# regs-internal register map
Registers are 32-bit, access not given, no defined reset value unless marked. A register's access mark holds for its fields unless they carry their own. Addresses are absolute; registers are grouped by the start of their names; [hi:lo] are bit positions; {n}, {i} and the like mark numbered series; 'fields as' and 'values as' point back to an identical list.

## MEM
{0x40005000+4i} MEM_PROT_{i} (i=0..7)
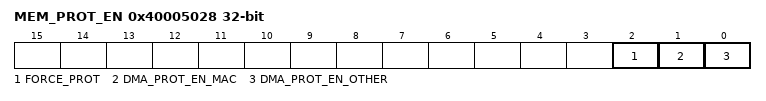
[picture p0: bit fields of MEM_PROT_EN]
0x40005028 MEM_PROT_EN
  [2] FORCE_PROT, [1] DMA_PROT_EN_MAC, [0] DMA_PROT_EN_OTHER

## WDOG
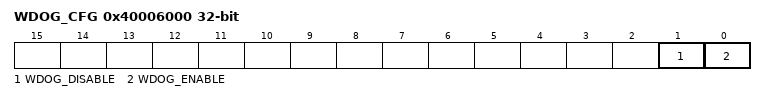
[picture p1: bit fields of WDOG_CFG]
0x40006000 WDOG_CFG
  [1] WDOG_DISABLE, [0] WDOG_ENABLE
0x40006004 WDOG_KEY
  [15:0] WDOG_KEY_FIELD
0x40006008 WDOG_RESET

## CAL
0x40007000 CAL_ADC_DATA
  [15:0] CAL_ADC_DATA
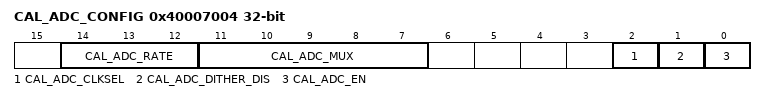
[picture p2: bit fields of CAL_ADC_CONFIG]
0x40007004 CAL_ADC_CONFIG
  [14:12] CAL_ADC_RATE, [11:7] CAL_ADC_MUX, [2] CAL_ADC_CLKSEL, [1] CAL_ADC_DITHER_DIS, [0] CAL_ADC_EN

## FLASH
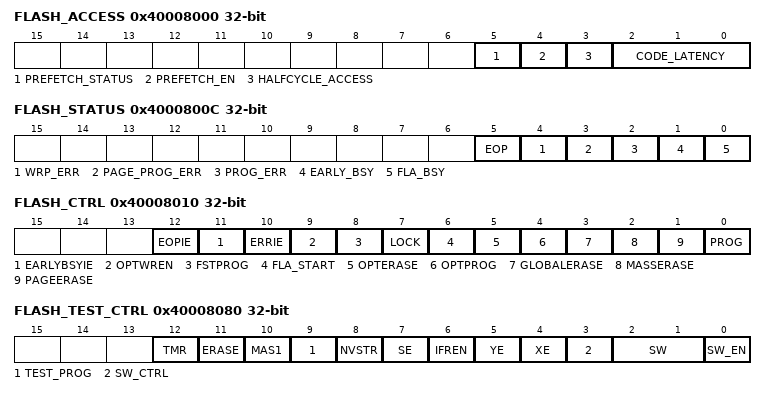
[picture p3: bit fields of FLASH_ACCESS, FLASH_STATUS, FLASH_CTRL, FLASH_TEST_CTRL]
0x40008000 FLASH_ACCESS
  [5] PREFETCH_STATUS, [4] PREFETCH_EN, [3] HALFCYCLE_ACCESS, [2:0] CODE_LATENCY
0x4000800C FLASH_STATUS
  [5] EOP, [4] WRP_ERR, [3] PAGE_PROG_ERR, [2] PROG_ERR, [1] EARLY_BSY, [0] FLA_BSY
0x40008010 FLASH_CTRL
  [12] EOPIE, [11] EARLYBSYIE, [10] ERRIE, [9] OPTWREN, [8] FSTPROG, [7] LOCK, [6] FLA_START, [5] OPTERASE, [4] OPTPROG, [3] GLOBALERASE, [2] MASSERASE, [1] PAGEERASE, [0] PROG
0x40008014 FLASH_ADDR
  [31:0] FAR
0x40008080 FLASH_TEST_CTRL
  [12] TMR, [11] ERASE, [10] MAS1, [9] TEST_PROG, [8] NVSTR, [7] SE, [6] IFREN, [5] YE, [4] XE, [3] SW_CTRL, [2:1] SW, [0] SW_EN
0x40008084 FLASH_DATA0
  [31:0] FDR0

## EMU
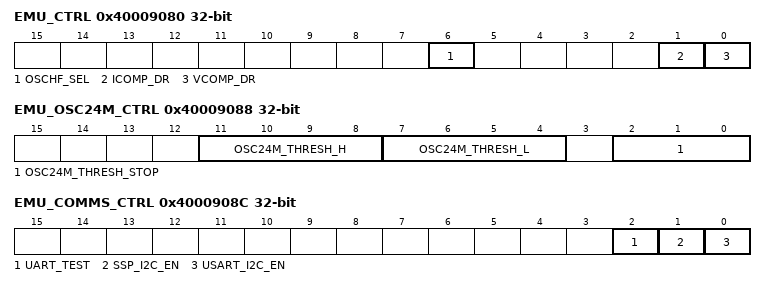
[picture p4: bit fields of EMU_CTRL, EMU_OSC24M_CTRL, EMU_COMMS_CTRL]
0x40009080 EMU_CTRL
  [6] OSCHF_SEL, [1] ICOMP_DR, [0] VCOMP_DR
0x40009084 EMU_PRESCALE_CTRL
  [0] PRE_REMAP
0x40009088 EMU_OSC24M_CTRL
  [11:8] OSC24M_THRESH_H, [7:4] OSC24M_THRESH_L, [2:0] OSC24M_THRESH_STOP
0x4000908C EMU_COMMS_CTRL
  [2] UART_TEST, [1] SSP_I2C_EN, [0] USART_I2C_EN
0x40009090 EMU_RESET_CTRL
  [0] RESET_DIS

## MON
0x40009100 MON_GPIO_H
  [7:0] MON_GPIO_H
0x40009104 MON_GPIO_L
  [15:0] MON_GPIO_L
0x40009108 MON_GPIO_O_H
  [7:0] MON_GPIO_O_H
0x4000910C MON_GPIO_O_L
  [15:0] MON_GPIO_O_L
0x40009110 MON_GPIO_OE_H
  [7:0] MON_GPIO_OE_H
0x40009114 MON_GPIO_OE_L
  [15:0] MON_GPIO_OE_L
0x40009118 MON_GPIO_PUE_H
  [7:0] MON_GPIO_PUE_H
0x4000911C MON_GPIO_PUE_L
  [15:0] MON_GPIO_PUE_L
0x40009120 MON_GPIO_PDE_H
  [7:0] MON_GPIO_PDE_H
0x40009124 MON_GPIO_PDE_L
  [15:0] MON_GPIO_PDE_L
0x40009128 MON_ATEST_CTRL
  [7:0] ATEST_CTRL
0x4000912C MON_ATEST_SEL
  [4:0] ATEST_SEL
0x40009130 MON_OSC24M_BIAS
  [3:0] OSC24M_BIAS
0x40009134 MON_OSCHF_TUNE
  [4:0] OSCHF_TUNE
0x40009138 MON_OSCRC_TUNE
  [3:0] OSCRC_TUNE
0x4000913C MON_GPIO_SC
  [0] GPIO_SC
0x40009140 MON_VREG_1V8_TRIM
  [2:0] VREG_1V8_TRIM
0x40009144 MON_VREG_1V2_TRIM
  [2:0] VREG_1V2_TRIM

## XBAR
{0x40009200+8i} XBAR_I{i} (i=0..23)
  [4:0] SEL
{0x40009204+8i} XBAR_O{i} (i=0..23)
  [4:0] SEL

## RAM
0x40009300 RAM_COUNT_BIG
  [15:0] RAM_COUNT_BIG
0x40009304 RAM_COUNT_SMALL
  [15:0] RAM_COUNT_SMALL
0x40009308 RAM_COUNT_WAIT
  [15:0] RAM_COUNT_WAIT

## SEC
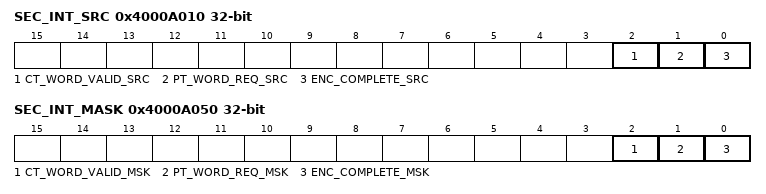
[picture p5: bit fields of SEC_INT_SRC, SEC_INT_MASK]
0x4000A010 SEC_INT_SRC
  [2] CT_WORD_VALID_SRC, [1] PT_WORD_REQ_SRC, [0] ENC_COMPLETE_SRC
0x4000A050 SEC_INT_MASK
  [2] CT_WORD_VALID_MSK, [1] PT_WORD_REQ_MSK, [0] ENC_COMPLETE_MSK

## INT
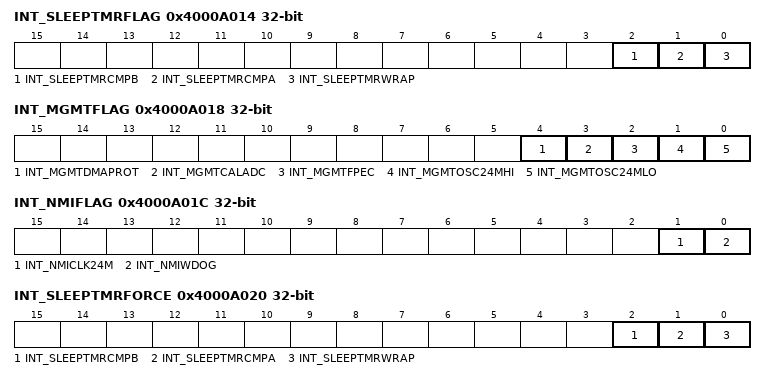
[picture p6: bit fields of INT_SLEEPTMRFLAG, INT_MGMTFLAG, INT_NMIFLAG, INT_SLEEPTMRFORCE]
0x4000A014 INT_SLEEPTMRFLAG
  [2] INT_SLEEPTMRCMPB, [1] INT_SLEEPTMRCMPA, [0] INT_SLEEPTMRWRAP
0x4000A018 INT_MGMTFLAG
  [4] INT_MGMTDMAPROT, [3] INT_MGMTCALADC, [2] INT_MGMTFPEC, [1] INT_MGMTOSC24MHI, [0] INT_MGMTOSC24MLO
0x4000A01C INT_NMIFLAG
  [1] INT_NMICLK24M, [0] INT_NMIWDOG
0x4000A020 INT_SLEEPTMRFORCE
  [2] INT_SLEEPTMRCMPB, [1] INT_SLEEPTMRCMPA, [0] INT_SLEEPTMRWRAP
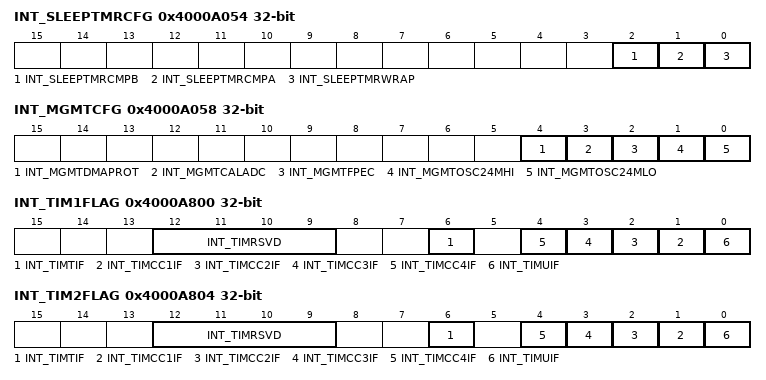
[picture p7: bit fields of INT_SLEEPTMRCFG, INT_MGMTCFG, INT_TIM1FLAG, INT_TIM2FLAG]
0x4000A054 INT_SLEEPTMRCFG
  [2] INT_SLEEPTMRCMPB, [1] INT_SLEEPTMRCMPA, [0] INT_SLEEPTMRWRAP
0x4000A058 INT_MGMTCFG
  fields as INT_MGMTFLAG
0x4000A800 INT_TIM1FLAG
  [12:9] INT_TIMRSVD, [6] INT_TIMTIF, [n] INT_TIMCC{n}IF (n=1..4), [0] INT_TIMUIF
0x4000A804 INT_TIM2FLAG
  fields as INT_TIM1FLAG
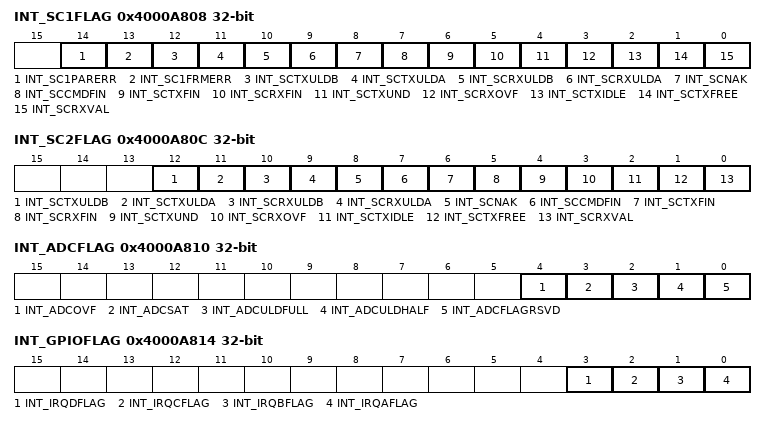
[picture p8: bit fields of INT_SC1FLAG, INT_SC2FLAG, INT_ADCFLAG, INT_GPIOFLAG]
0x4000A808 INT_SC1FLAG
  [14] INT_SC1PARERR, [13] INT_SC1FRMERR, [12] INT_SCTXULDB, [11] INT_SCTXULDA, [10] INT_SCRXULDB, [9] INT_SCRXULDA, [8] INT_SCNAK, [7] INT_SCCMDFIN, [6] INT_SCTXFIN, [5] INT_SCRXFIN, [4] INT_SCTXUND, [3] INT_SCRXOVF, [2] INT_SCTXIDLE, [1] INT_SCTXFREE, [0] INT_SCRXVAL
0x4000A80C INT_SC2FLAG
  [12] INT_SCTXULDB, [11] INT_SCTXULDA, [10] INT_SCRXULDB, [9] INT_SCRXULDA, [8] INT_SCNAK, [7] INT_SCCMDFIN, [6] INT_SCTXFIN, [5] INT_SCRXFIN, [4] INT_SCTXUND, [3] INT_SCRXOVF, [2] INT_SCTXIDLE, [1] INT_SCTXFREE, [0] INT_SCRXVAL
0x4000A810 INT_ADCFLAG
  [4] INT_ADCOVF, [3] INT_ADCSAT, [2] INT_ADCULDFULL, [1] INT_ADCULDHALF, [0] INT_ADCFLAGRSVD
0x4000A814 INT_GPIOFLAG
  [3] INT_IRQDFLAG, [2] INT_IRQCFLAG, [1] INT_IRQBFLAG, [0] INT_IRQAFLAG
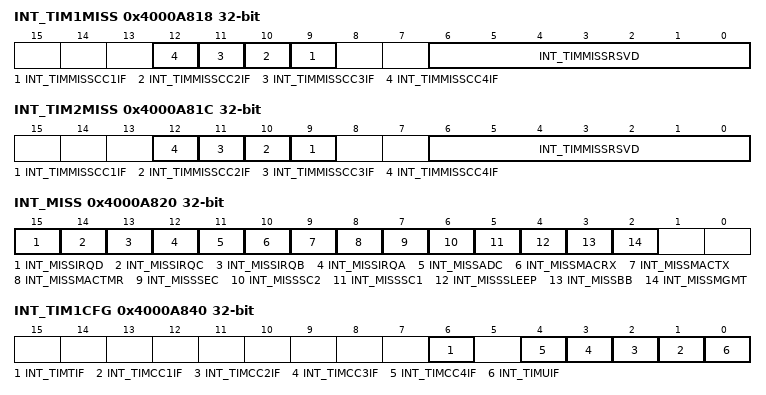
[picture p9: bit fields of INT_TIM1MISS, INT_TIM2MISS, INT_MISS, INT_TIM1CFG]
0x4000A818 INT_TIM1MISS
  [n+8] INT_TIMMISSCC{n}IF (n=1..4), [6:0] INT_TIMMISSRSVD
0x4000A81C INT_TIM2MISS
  [n+8] INT_TIMMISSCC{n}IF (n=1..4), [6:0] INT_TIMMISSRSVD
0x4000A820 INT_MISS
  [15] INT_MISSIRQD, [14] INT_MISSIRQC, [13] INT_MISSIRQB, [12] INT_MISSIRQA, [11] INT_MISSADC, [10] INT_MISSMACRX, [9] INT_MISSMACTX, [8] INT_MISSMACTMR, [7] INT_MISSSEC, [6] INT_MISSSC2, [5] INT_MISSSC1, [4] INT_MISSSLEEP, [3] INT_MISSBB, [2] INT_MISSMGMT
0x4000A840 INT_TIM1CFG
  [6] INT_TIMTIF, [n] INT_TIMCC{n}IF (n=1..4), [0] INT_TIMUIF
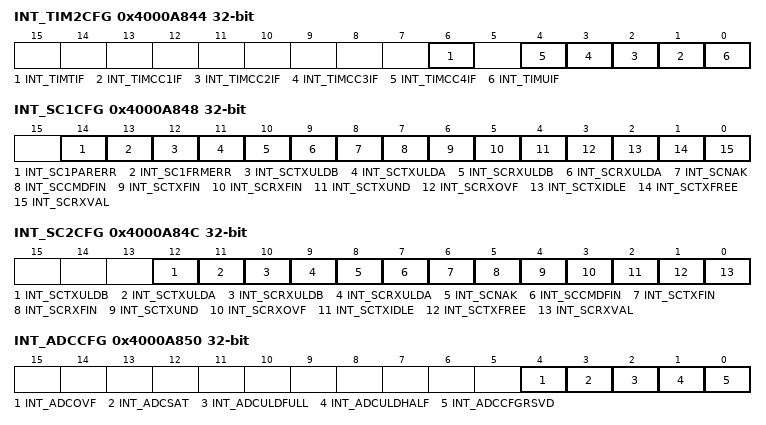
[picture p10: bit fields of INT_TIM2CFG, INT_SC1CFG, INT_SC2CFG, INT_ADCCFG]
0x4000A844 INT_TIM2CFG
  [6] INT_TIMTIF, [n] INT_TIMCC{n}IF (n=1..4), [0] INT_TIMUIF
0x4000A848 INT_SC1CFG
  fields as INT_SC1FLAG
0x4000A84C INT_SC2CFG
  fields as INT_SC2FLAG
0x4000A850 INT_ADCCFG
  [4] INT_ADCOVF, [3] INT_ADCSAT, [2] INT_ADCULDFULL, [1] INT_ADCULDHALF, [0] INT_ADCCFGRSVD
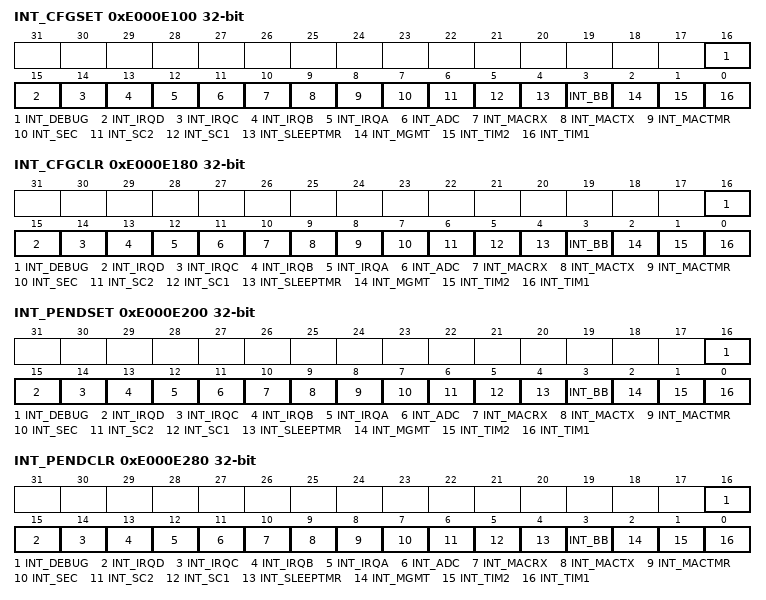
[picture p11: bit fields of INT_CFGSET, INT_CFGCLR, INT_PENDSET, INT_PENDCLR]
0xE000E100 INT_CFGSET
  [16] INT_DEBUG, [15] INT_IRQD, [14] INT_IRQC, [13] INT_IRQB, [12] INT_IRQA, [11] INT_ADC, [10] INT_MACRX, [9] INT_MACTX, [8] INT_MACTMR, [7] INT_SEC, [6] INT_SC2, [5] INT_SC1, [4] INT_SLEEPTMR, [3] INT_BB, [2] INT_MGMT, [1] INT_TIM2, [0] INT_TIM1
0xE000E180 INT_CFGCLR
  fields as INT_CFGSET
0xE000E200 INT_PENDSET
  fields as INT_CFGSET
0xE000E280 INT_PENDCLR
  fields as INT_CFGSET
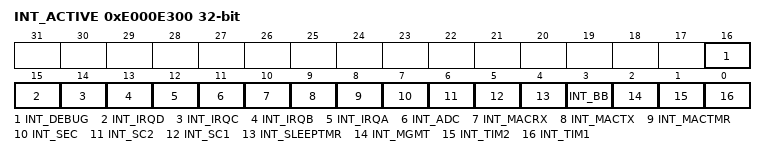
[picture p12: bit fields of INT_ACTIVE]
0xE000E300 INT_ACTIVE
  fields as INT_CFGSET
